AUTOSAR XML (schema 4-0-3)
standard types defined: Boolean, UInt16, UInt32, UInt8
package /AUTOSAR_Platform/DataConstrs
  range DC_Boolean: raw 0..1
  range DC_UInt16: raw 0..65535
  range DC_UInt8: raw 0..255
package /PATAC/MSM/ComponentTypes
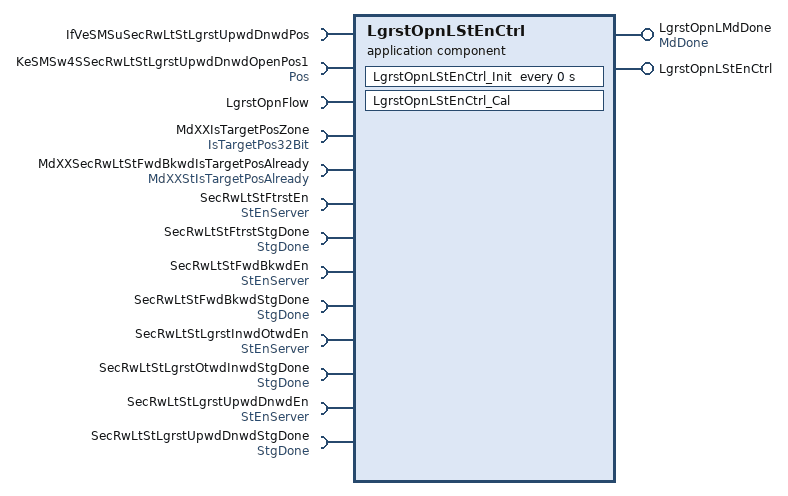
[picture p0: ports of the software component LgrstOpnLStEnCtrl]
  application sw component type LgrstOpnLStEnCtrl
    provide port LgrstOpnLMdDone: nonqueued-sender-com-spec{data-element=MdDone/Val, init-value=0}, provided-interface=MdDone
    provide port LgrstOpnLStEnCtrl: server-com-spec{operation=LgrstOpnLStEnCtrl/Cal, queue-length=1}, provided-interface=LgrstOpnLStEnCtrl
    13 x require port:
      IfVeSMSuSecRwLtStLgrstUpwdDnwdPos: nonqueued-receiver-com-spec{data-element=IfVeSMSuSecRwLtStLgrstUpwdDnwdPos/Val, filter=data-filter-type=ALWAYS, init-value=0}, required-interface=IfVeSMSuSecRwLtStLgrstUpwdDnwdPos
      KeSMSw4SSecRwLtStLgrstUpwdDnwdOpenPos1: parameter-require-com-spec{init-value=0, parameter=Val}, required-interface=Pos
      LgrstOpnFlow: client-com-spec=LgrstOpnFlow/Cal, required-interface=LgrstOpnFlow
      MdXXIsTargetPosZone: nonqueued-receiver-com-spec{data-element=IsTargetPos32Bit/Val, filter=data-filter-type=ALWAYS, init-value=0}, required-interface=IsTargetPos32Bit
      MdXXSecRwLtStFwdBkwdIsTargetPosAlready: nonqueued-receiver-com-spec{data-element=MdXXStIsTargetPosAlready/Val, filter=data-filter-type=ALWAYS, init-value=0}, required-interface=MdXXStIsTargetPosAlready
      SecRwLtStFtrstEn: required-com-specs=[Clear, Get, Set], required-interface=StEnServer
      SecRwLtStFtrstStgDone: nonqueued-receiver-com-spec{data-element=StgDone/Val, filter=data-filter-type=ALWAYS, init-value=0}, required-interface=StgDone
      SecRwLtStFwdBkwdEn: required-com-specs=[Clear, Get, Set], required-interface=StEnServer
      SecRwLtStFwdBkwdStgDone: nonqueued-receiver-com-spec{data-element=StgDone/Val, filter=data-filter-type=ALWAYS, init-value=0}, required-interface=StgDone
      SecRwLtStLgrstInwdOtwdEn: required-com-specs=[Clear, Get, Set], required-interface=StEnServer
      SecRwLtStLgrstOtwdInwdStgDone: nonqueued-receiver-com-spec{data-element=StgDone/Val, filter=data-filter-type=ALWAYS, init-value=0}, required-interface=StgDone
      SecRwLtStLgrstUpwdDnwdEn: required-com-specs=[Clear, Get, Set], required-interface=StEnServer
      SecRwLtStLgrstUpwdDnwdStgDone: nonqueued-receiver-com-spec{data-element=StgDone/Val, filter=data-filter-type=ALWAYS, init-value=0}, required-interface=StgDone
    behavior LgrstOpnLStEnCtrl_InternalBehavior
      operation invoked event OIT_LgrstOpnLStEnCtrl_Cal_LgrstOpnLStEnCtrl_Cal: start-on-event=LgrstOpnLStEnCtrl_Cal, operation=LgrstOpnLStEnCtrl.Cal
      timing event LgrstOpnLStEnCtrl_InitEvent: start-on-event=LgrstOpnLStEnCtrl_Init, period=0
      runnable LgrstOpnLStEnCtrl_Cal
        data-receive-point-by-arguments:
          7 x access:
            REC_IfVeSMSuSecRwLtStLgrstUpwdDnwdPos_Val: accessed-variable=IfVeSMSuSecRwLtStLgrstUpwdDnwdPos.Val
            REC_MdXXIsTargetPosZone_Val: accessed-variable=MdXXIsTargetPosZone.Val
            REC_MdXXSecRwLtStFwdBkwdIsTargetPosAlready_Val: accessed-variable=MdXXSecRwLtStFwdBkwdIsTargetPosAlready.Val
            REC_SecRwLtStFtrstStgDone_Val: accessed-variable=SecRwLtStFtrstStgDone.Val
            REC_SecRwLtStFwdBkwdStgDone_Val: accessed-variable=SecRwLtStFwdBkwdStgDone.Val
            REC_SecRwLtStLgrstOtwdInwdStgDone_Val: accessed-variable=SecRwLtStLgrstOtwdInwdStgDone.Val
            REC_SecRwLtStLgrstUpwdDnwdStgDone_Val: accessed-variable=SecRwLtStLgrstUpwdDnwdStgDone.Val
        data-send-points:
          access SEND_LgrstOpnLMdDone_Val: accessed-variable=LgrstOpnLMdDone.Val
        parameter access PA_KeSMSw4SSecRwLtStLgrstUpwdDnwdOpenPos1_Val: accessed-parameter=KeSMSw4SSecRwLtStLgrstUpwdDnwdOpenPos1.Val
        9 x sync call, all with timeout=0:
          SC_LgrstOpnFlow_Cal: operation=LgrstOpnFlow.Cal
          SC_SecRwLtStFtrstEn_Clear: operation=SecRwLtStFtrstEn.Clear
          SC_SecRwLtStFtrstEn_Set: operation=SecRwLtStFtrstEn.Set
          SC_SecRwLtStFwdBkwdEn_Clear: operation=SecRwLtStFwdBkwdEn.Clear
          SC_SecRwLtStFwdBkwdEn_Set: operation=SecRwLtStFwdBkwdEn.Set
          SC_SecRwLtStLgrstInwdOtwdEn_Clear: operation=SecRwLtStLgrstInwdOtwdEn.Clear
          SC_SecRwLtStLgrstInwdOtwdEn_Set: operation=SecRwLtStLgrstInwdOtwdEn.Set
          SC_SecRwLtStLgrstUpwdDnwdEn_Clear: operation=SecRwLtStLgrstUpwdDnwdEn.Clear
          SC_SecRwLtStLgrstUpwdDnwdEn_Set: operation=SecRwLtStLgrstUpwdDnwdEn.Set
      runnable LgrstOpnLStEnCtrl_Init
        parameter access PA_KeSMSw4SSecRwLtStLgrstUpwdDnwdOpenPos1_Val: accessed-parameter=KeSMSw4SSecRwLtStLgrstUpwdDnwdOpenPos1.Val
  swc implementation LgrstOpnLStEnCtrl_Implementation: behavior=LgrstOpnLStEnCtrl_InternalBehavior
    code-descriptors:
      code Default: artifact-descriptors=autosar-engineering-object={short-label=Default, category=SWSRC}
package /PATAC/MSM/ModeAdjust/CalPortInterface
  parameter interface Pos
    parameter data prototype Val: sw-calibration-access=READ-WRITE, type=UInt16
package /PATAC/MSM/ModeAdjust/PortInterface
  client server interface LgrstOpnFlow
    operation Cal
      9 x arg, all with server-argument-impl-policy=USE-ARGUMENT-TYPE:
        LgrstUpwdDnwdPos: type=UInt16, direction=IN
        LgrstUpwdDnwdOpenPos1: type=UInt16, direction=IN
        LgrstUpwdStgDone: type=Boolean, direction=IN
        FtrstStgDone: type=Boolean, direction=IN
        LgrstInwdStgDone: type=Boolean, direction=IN
        Failflg: type=Boolean, direction=OUT
        LgrstInwdOtwdEn: type=Boolean, direction=OUT
        LgrstUpwdDnwdEn: type=Boolean, direction=OUT
        FtrstEn: type=Boolean, direction=OUT
  client server interface LgrstOpnLStEnCtrl
    operation Cal
  client server interface StEnServer
    operation Clear
      arg data: type=UInt8, direction=IN, server-argument-impl-policy=USE-ARGUMENT-TYPE
    operation Get
      arg data: type=UInt32, direction=OUT, server-argument-impl-policy=USE-ARGUMENT-TYPE
    operation Set
      arg data: type=UInt8, direction=IN, server-argument-impl-policy=USE-ARGUMENT-TYPE
  4 x sender receiver interface:
    IsTargetPos32Bit: invalidation-policy{data-element=IsTargetPos32Bit/Val, handle-invalid=DONT-INVALIDATE}
      data Val: type=UInt32
    MdDone: invalidation-policy{data-element=MdDone/Val, handle-invalid=DONT-INVALIDATE}
      data Val: type=UInt8
    MdXXStIsTargetPosAlready: invalidation-policy{data-element=MdXXStIsTargetPosAlready/Val, handle-invalid=DONT-INVALIDATE}
      data Val: type=UInt32
    StgDone: invalidation-policy{data-element=StgDone/Val, handle-invalid=DONT-INVALIDATE}
      data Val: type=Boolean
package /PATAC/MSM/PortInterfaces
  sender receiver interface IfVeSMSuSecRwLtStLgrstUpwdDnwdPos: invalidation-policy{data-element=IfVeSMSuSecRwLtStLgrstUpwdDnwdPos/Val, handle-invalid=DONT-INVALIDATE}
    data Val: type=UInt16
